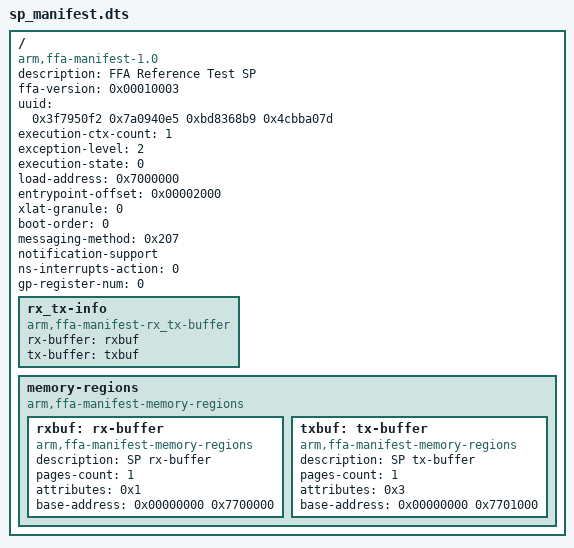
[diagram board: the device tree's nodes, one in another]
/*
 * This file is a Partition Manifest (PM) for my minimal reference secure partition (SP)
 *
 */
/dts-v1/;

/ {
	compatible = "arm,ffa-manifest-1.0";

	/* Properties */
	description = "FFA Reference Test SP";
	ffa-version = <0x00010003>; /* 31:16 - Major, 15:0 - Minor */

	uuid = <0x3f7950f2 0x7a0940e5 0xbd8368b9 0x4cbba07d>;

	execution-ctx-count = <1>;
	exception-level = <2>; /* S-EL1 */
	execution-state = <0>; /* AARCH64 */

	load-address = <0x7000000>;
	entrypoint-offset = <0x00002000>;

	xlat-granule = <0>; /* 4KiB */

	boot-order = <0>;

	messaging-method = <0x207>; /* Direct messaging via DIRECT_REQ and DIRECT_REQ2 and Indirect Messaging */
	
	/* needed for receiving framework notifications about Rx_Tx buffer msg receipt */
	notification-support;

	ns-interrupts-action = <0>; /* Queue NS interrupts */

	/* Boot protocol */
	gp-register-num = <0>;

	rx_tx-info{
		compatible = "arm,ffa-manifest-rx_tx-buffer";
		rx-buffer = <&rxbuf>;
		tx-buffer = <&txbuf>;
	};
	
	/* TODO: explore how to decide the physical base-address for Rx/Tx buffers */
	memory-regions {
		compatible = "arm,ffa-manifest-memory-regions";

		rxbuf: rx-buffer {
			compatible = "arm,ffa-manifest-memory-regions";
			description = "SP rx-buffer";
			pages-count = <1>;
			attributes = <0x1>; /* read-only for Rx buffer */
			base-address = <0x00000000 0x7700000>;
		};

		txbuf: tx-buffer {
			compatible = "arm,ffa-manifest-memory-regions";
			description = "SP tx-buffer";
			pages-count = <1>;
			attributes = <0x3>; /* read-write for Tx buffer */
			base-address = <0x00000000 0x7701000>;
		};

	};
};
